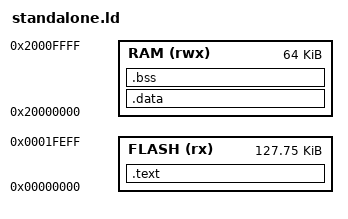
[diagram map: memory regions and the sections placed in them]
MEMORY
{
    FLASH (rx) : ORIGIN = 0x00000000, LENGTH = 0x001FF00
    RAM (rwx) : ORIGIN = 0x20000000, LENGTH = 0x00010000
}

SECTIONS
{
    .text :
    {
        _start_text = .;
        KEEP(*(.isr_vector))
        . = 0x3c0;
        KEEP(*(.stage1_config))
        . = 0x400;
        KEEP(*(.flash_config))
        . = ALIGN(8);
        *(.text*)
        *(.rodata*)
        . = ALIGN(4);
        _end_text = .;
    } > FLASH

    _stored_data = .;

    .data : AT (_stored_data)
    {
        _start_data = .;
        KEEP(*(.data*))
        . = ALIGN(4);
        KEEP(*(.ramcode))
        . = ALIGN(4);
        _end_data = .;
    } > RAM

    .bss :
    {
        _start_bss = .;
        *(.bss*)
        *(COMMON)
        . = ALIGN(4);
        _end_bss = .;
        _end = .;
    } > RAM
}

PROVIDE(_start_heap = _end);
PROVIDE(_end_stack  = ORIGIN(RAM) + LENGTH(RAM));
